# CY8C5888LTI_LP097 register map
File version: 0.1
Registers are 8-bit, read-write, no defined reset value unless marked. A register's access mark holds for its fields unless they carry their own. Offsets are from the block's base; [hi:lo] are bit positions; {n}, {i} and the like mark numbered series; 'fields as' and 'values as' point back to an identical list.

## PWM_1
Base 0x00000000
0x40006422 PWM_1_COMPARE_1 16-bit — UDB.D0 - Assigned Compare1 Value
0x40006432 PWM_1_COMPARE_2 16-bit — UDB.D1 - Assigned Compare2 Value
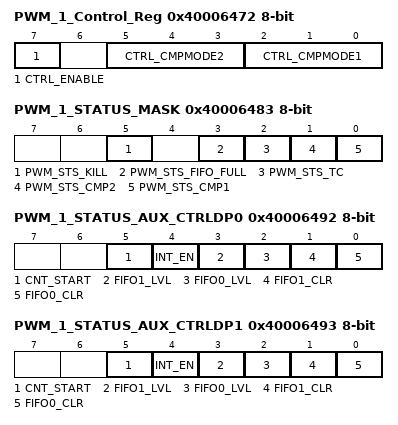
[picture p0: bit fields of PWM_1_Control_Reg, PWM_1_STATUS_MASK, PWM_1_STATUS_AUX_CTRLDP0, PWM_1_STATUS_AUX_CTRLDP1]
0x40006472 PWM_1_Control_Reg — UDB Control Register - Assigned Control Register Value
  [7] CTRL_ENABLE — Enable the PWM
  [5:3] CTRL_CMPMODE2 — Compare mode 2
  [2:0] CTRL_CMPMODE1 — Compare mode 1
0x40006483 PWM_1_STATUS_MASK — UDB Status bits Interrupt Mask Enable Register
  [5] PWM_STS_KILL ro — Enables the Interrupt on Kill
  [3] PWM_STS_FIFO_FULL ro — FIFO Full Status Mask
  [2] PWM_STS_TC ro — Enables the Interrupt on Terminal Count
  [1] PWM_STS_CMP2 ro — Enables the Interrupt on Compare 2
  [0] PWM_STS_CMP1 ro — Enables the Interrupt on Compare 1
0x40006492 PWM_1_STATUS_AUX_CTRLDP0 — UDB Auxilliary Control Register
  [5] CNT_START — FIFO0 clear
    0=E_CNT_START0 (Disable counter); 1=E_CNT_START1 (Enable counter)
  [4] INT_EN
    0=E_INT_EN0 (Interrupt disabled); 1=E_INT_EN1 (Interrupt enabled)
  [3] FIFO1_LVL — FIFO level
    0=E_FIFO_LVL_0 (FIFO LVL: input mode: FIFO not full; output mode: FIFO not empty); 1=E_FIFO_LVL_1 (FIFO LVL: input mode: FIFO at least 1/2 empty; output mode: FIFO at least 1/2 full)
  [2] FIFO0_LVL — FIFO level
    values as FIFO1_LVL
  [1] FIFO1_CLR — FIFO1 clear
    0=E_FIFO_CLR_0 (Normal FIFO operation); 1=E_FIFO_CLR_1 (Clear FIFO state)
  [0] FIFO0_CLR — FIFO0 clear
    values as FIFO1_CLR
0x40006493 PWM_1_STATUS_AUX_CTRLDP1 — UDB Auxilliary Control Register
  fields as PWM_1_STATUS_AUX_CTRLDP0

## PWM_2
Base 0x00000000
0x40006420 PWM_2_COMPARE_1 16-bit — UDB.D0 - Assigned Compare1 Value
0x40006430 PWM_2_COMPARE_2 16-bit — UDB.D1 - Assigned Compare2 Value
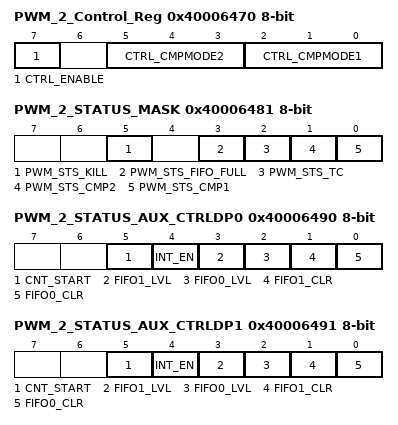
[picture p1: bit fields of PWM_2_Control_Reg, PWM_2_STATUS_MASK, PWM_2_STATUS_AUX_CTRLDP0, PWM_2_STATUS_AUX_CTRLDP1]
0x40006470 PWM_2_Control_Reg — UDB Control Register - Assigned Control Register Value
  [7] CTRL_ENABLE — Enable the PWM
  [5:3] CTRL_CMPMODE2 — Compare mode 2
  [2:0] CTRL_CMPMODE1 — Compare mode 1
0x40006481 PWM_2_STATUS_MASK — UDB Status bits Interrupt Mask Enable Register
  [5] PWM_STS_KILL ro — Enables the Interrupt on Kill
  [3] PWM_STS_FIFO_FULL ro — FIFO Full Status Mask
  [2] PWM_STS_TC ro — Enables the Interrupt on Terminal Count
  [1] PWM_STS_CMP2 ro — Enables the Interrupt on Compare 2
  [0] PWM_STS_CMP1 ro — Enables the Interrupt on Compare 1
0x40006490 PWM_2_STATUS_AUX_CTRLDP0 — UDB Auxilliary Control Register
  [5] CNT_START — FIFO0 clear
    0=E_CNT_START0 (Disable counter); 1=E_CNT_START1 (Enable counter)
  [4] INT_EN
    0=E_INT_EN0 (Interrupt disabled); 1=E_INT_EN1 (Interrupt enabled)
  [3] FIFO1_LVL — FIFO level
    0=E_FIFO_LVL_0 (FIFO LVL: input mode: FIFO not full; output mode: FIFO not empty); 1=E_FIFO_LVL_1 (FIFO LVL: input mode: FIFO at least 1/2 empty; output mode: FIFO at least 1/2 full)
  [2] FIFO0_LVL — FIFO level
    values as FIFO1_LVL
  [1] FIFO1_CLR — FIFO1 clear
    0=E_FIFO_CLR_0 (Normal FIFO operation); 1=E_FIFO_CLR_1 (Clear FIFO state)
  [0] FIFO0_CLR — FIFO0 clear
    values as FIFO1_CLR
0x40006491 PWM_2_STATUS_AUX_CTRLDP1 — UDB Auxilliary Control Register
  fields as PWM_2_STATUS_AUX_CTRLDP0

## Counter_1
Base 0x00000000
0x400043A3 Counter_1_GLOBAL_ENABLE — PM.ACT.CFG
  [3:0] en_timer — Enable timer/counters.
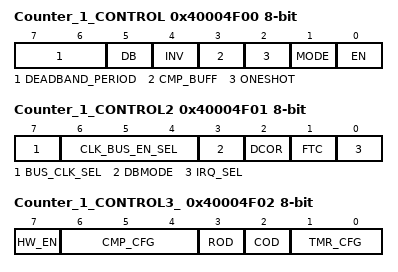
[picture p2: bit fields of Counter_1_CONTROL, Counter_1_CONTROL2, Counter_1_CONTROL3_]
0x40004F00 Counter_1_CONTROL — TMRx.CFG0
  [7:6] DEADBAND_PERIOD
  [5] DB — Deadband mode--Deadband phases phi1 and phi2 are outputted on CMP and TC output pins respectively.
    0=Timer (CMP and TC are output.); 1=Deadband (PHI1 (instead of CMP) and PHI2 (instead of TC) are output.)
  [4] INV — Invert sense of TIMEREN signal
  [3] CMP_BUFF — Buffer compare register. Compare register updates only on timer terminal count.
  [2] ONESHOT — Timer stops upon reaching stop condition defined by TMR_CFG bits. Can be restarted by asserting TIMER RESET or disabling and re-enabling block.
  [1] MODE — Mode. (0 = Timer; 1 = Comparator)
    0=Timer mode. CNT/CMP register holds timer count value.; 1=Comparator mode. CNT/CMP register holds comparator threshold value.
  [0] EN — Enables timer/comparator.
0x40004F01 Counter_1_CONTROL2 — TMRx.CFG1
  [7] BUS_CLK_SEL — Bus Clock selection.
  [6:4] CLK_BUS_EN_SEL — Digital Global Clock selection.
  [3] DBMODE — Deadband mode (asynchronous/synchronous). CMP output pin is also affected when not in deadband mode (CFG0.DEADBAND).
  [2] DCOR — Disable Clear on Read (DCOR) of Status Register SR0.
  [1] FTC — First Terminal Count (FTC). Setting this bit forces a single pulse on the TC pin when first enabled.
    0=Disable_FTC (Disable the single cycle pulse, which signifies the timer is starting.); 1=Enable_FTC (Enable the single cycle pulse, which signifies the timer is starting.)
  [0] IRQ_SEL — Irq selection. (0 = raw interrupts; 1 = status register interrupts)
0x40004F02 Counter_1_CONTROL3_ — TMRx.CFG2
  [7] HW_EN — When set Timer Enable controls counting.
  [6:4] CMP_CFG — Comparator configurations
    0=Equal (Compare Equal); 1=Less_than (Compare Less Than); 2=Less_than_or_equal (Compare Less Than or Equal .); 3=Greater (Compare Greater Than .); 4=Greater_than_or_equal (Compare Greater Than or Equal)
  [3] ROD — Reset On Disable (ROD). Resets internal state of output logic
  [2] COD — Clear On Disable (COD). Clears or gates outputs to zero.
  [1:0] TMR_CFG — Timer configuration (MODE = 0): 000 = Continuous; 001 = Pulsewidth; 010 = Period; 011 = Stop on IRQ
    0=Continuous (Timer runs while EN bit of CFG0 register is set to '1'.); 1=Pulsewidth (Timer runs from positive to negative edge of TIMEREN.); 2=Period (Timer runs from positive to positive edge of TIMEREN.); 3=Irq (Timer runs until IRQ.)
0x40004F04 Counter_1_PERIOD 16-bit — TMRx.PER0 - Assigned Period
0x40004F06 Counter_1_COUNTER 16-bit — TMRx.CNT_CMP0 - Current Down Counter Value

## Opamp_1
Base 0x00000000
0x400043A4 PM_ACT_CFG4 — Active Power Mode Configuration Register 4
  [3:0] EN_OPAMP — Enables subsystems during active power mode
    0=Blk_0 (Enables analog linear output buffer for Opamp block 0); 2=Blk_1 (Enables analog linear output buffer for Opamp block 1); 4=Blk_2 (Enables analog linear output buffer for Opamp block 2); 8=Blk_3 (Enables analog linear output buffer for Opamp block 3)
0x400043B4 PM_STBY_CFG4 — Standby Power Mode Configuration Register 4
  [3:0] EN_OPAMP — Enables subsystems during standby power mode
    values as PM_ACT_CFG4.EN_OPAMP
0x40004620 OPAMP__TR0 — Analog Output Buffer Trim Register 0
  [4:0] offset_trim — Offset Trim: 420uV typical step size; +/- 6.8mV offset trimmable range
0x40004621 OPAMP__TR1 — Analog Output Buffer Trim Register 1
0x40005858 OPAMP__CR — Analog Output Buffer Configuration Register
  [1:0] pwr_mode — Power Mode
    0=Default_Fast (Default Power mode Fast); 1=Slow (Power Mode Slow); 2=Medium (Power Mode Medium); 3=Fast (Power Mode Fast)
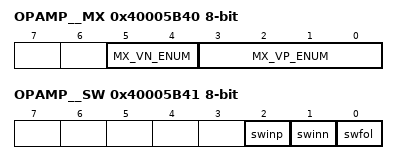
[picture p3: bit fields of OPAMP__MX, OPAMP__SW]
0x40005B40 OPAMP__MX — Analog Buffer Input Selection Register
  [5:4] MX_VN_ENUM — MUX select VN (Negative terminal input)
    0=OPAMP0_MX_VN_DEFAULT (Default - Not Connected (NC)); 1=OPAMP0_MX_VN_AG4 (MUX Selection AGL(4)); 2=OPAMP0_MX_VN_AG6 (MUX Selection AGL(6)); 3=OPAMP0_MX_VN_0x3 (Reserved (NC))
  [3:0] MX_VP_ENUM — MUX select VP (Positive terminal input)
    0=OPAMP0_MX_VP_DEFAULT (Default - Not Connected (NC)); {v}=OPAMP0_MX_VP_AG{v+3} (MUX Selection AGL({v+3})) (v=1..4); {v}=OPAMP0_MX_VP_ABUS{v-5} (MUX Selection ABUSL({v-5})) (v=5..8); 9=OPAMP0_MX_VP_VREF (MUX Selection: OPAMP Voltage Reference); {v}=OPAMP0_MX_VP_H_{0x0+v} (Reserved (NC)) (v=10..15)
0x40005B41 OPAMP__SW — Analog Buffer Routing Switch Register
  [2] swinp — Switch Enable Positive Input
  [1] swinn — Switch Enable Negative Input
  [0] swfol — Switch Enable Follow

## BitCounterDec
Base 0x00000000
0x40006407 BitCounterDec_COUNTER — UDB.A0 - Current Counter Value
0x40006427 BitCounterDec_PERIOD — UDB.D0 - Assigned Period
0x40006437 BitCounterDec_COMPARE — UDB.D1 - Assigned Compare Value
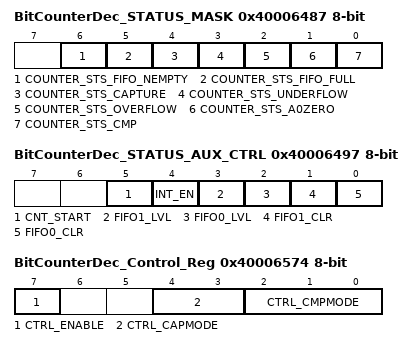
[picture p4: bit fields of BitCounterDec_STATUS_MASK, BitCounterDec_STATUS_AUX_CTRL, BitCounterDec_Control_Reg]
0x40006487 BitCounterDec_STATUS_MASK — UDB Status bits Interrupt Mask Enable Register
  [6] COUNTER_STS_FIFO_NEMPTY — FIFO Not Empty Status
  [5] COUNTER_STS_FIFO_FULL — FIFO Full Status
  [4] COUNTER_STS_CAPTURE — Capture Status
  [3] COUNTER_STS_UNDERFLOW — Underflow status
  [2] COUNTER_STS_OVERFLOW — Overflow status
  [1] COUNTER_STS_A0ZERO — A0 Zero ouput status
  [0] COUNTER_STS_CMP — Compare output status
0x40006497 BitCounterDec_STATUS_AUX_CTRL — UDB Auxilliary Control Register
  [5] CNT_START — FIFO0 clear
    0=E_CNT_START0 (Disable counter); 1=E_CNT_START1 (Enable counter)
  [4] INT_EN
    0=E_INT_EN0 (Interrupt disabled); 1=E_INT_EN1 (Interrupt enabled)
  [3] FIFO1_LVL — FIFO level
    0=E_FIFO_LVL_0 (FIFO LVL: input mode: FIFO not full; output mode: FIFO not empty); 1=E_FIFO_LVL_1 (FIFO LVL: input mode: FIFO at least 1/2 empty; output mode: FIFO at least 1/2 full)
  [2] FIFO0_LVL — FIFO level
    values as FIFO1_LVL
  [1] FIFO1_CLR — FIFO1 clear
    0=E_FIFO_CLR_0 (Normal FIFO operation); 1=E_FIFO_CLR_1 (Clear FIFO state)
  [0] FIFO0_CLR — FIFO0 clear
    values as FIFO1_CLR
0x40006574 BitCounterDec_Control_Reg — UDB Control Register - Assigned Control Register Value
  [7] CTRL_ENABLE — Enable Counter
  [4:3] CTRL_CAPMODE — Capture mode
  [2:0] CTRL_CMPMODE — Compare mode
